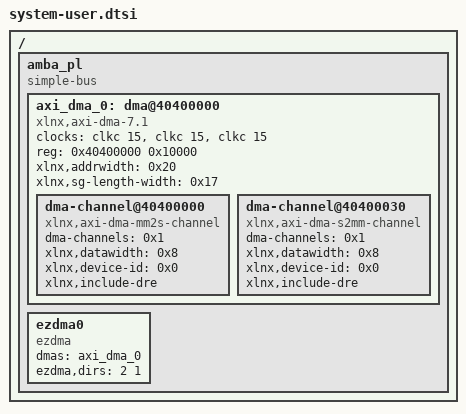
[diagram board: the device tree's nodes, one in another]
/include/ "system-conf.dtsi"
/ {
};

/ {
	amba_pl: amba_pl {
		#address-cells = <1>;
		#size-cells = <1>;
		compatible = "simple-bus";
		ranges ;
		axi_dma_0: dma@40400000 {
			#dma-cells = <1>;
			clock-names = "s_axi_lite_aclk", "m_axi_mm2s_aclk", "m_axi_s2mm_aclk";
			clocks = <&clkc 15>, <&clkc 15>, <&clkc 15>;
			compatible = "xlnx,axi-dma-7.1", "xlnx,axi-dma-1.00.a";
			reg = <0x40400000 0x10000>;
			xlnx,addrwidth = <0x20>;
			xlnx,sg-length-width = <0x17>;
			dma-channel@40400000 {
				compatible = "xlnx,axi-dma-mm2s-channel";
				dma-channels = <0x1>;
				xlnx,datawidth = <0x8>;
				xlnx,device-id = <0x0>;
				xlnx,include-dre ;
			};
			dma-channel@40400030 {
				compatible = "xlnx,axi-dma-s2mm-channel";
				dma-channels = <0x1>;
				xlnx,datawidth = <0x8>;
				xlnx,device-id = <0x0>;
				xlnx,include-dre ;
			};
		};
	    ezdma0 {
		compatible = "ezdma";

		dmas = <&axi_dma_0>;
		dma-names = "loop_tx", "loop_rx";  
		ezdma,dirs = <2 1>;                 
	    };
	};
};
